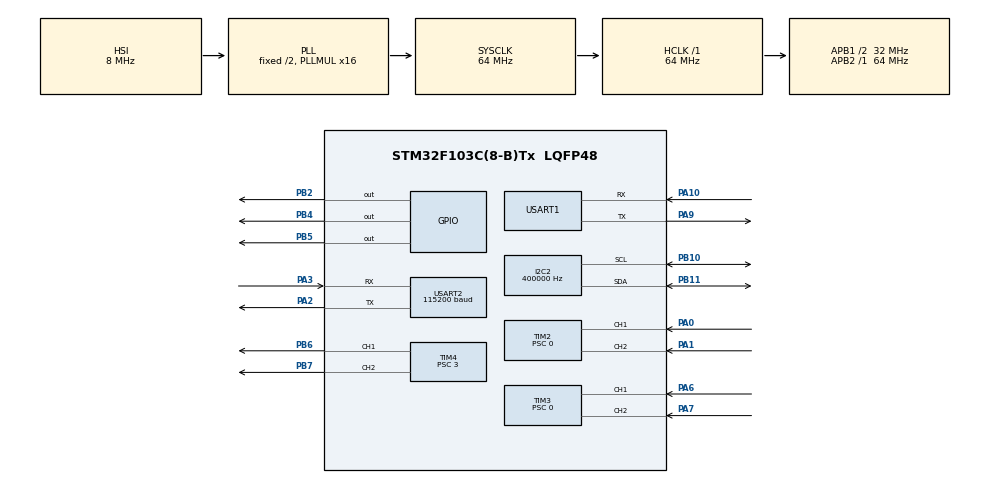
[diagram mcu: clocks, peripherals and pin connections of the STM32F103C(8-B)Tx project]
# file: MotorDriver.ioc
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Mcu.Family=STM32F1
TIM4.Channel-PWM\ Generation1\ CH1=TIM_CHANNEL_1
TIM4.AutoReloadPreload=TIM_AUTORELOAD_PRELOAD_ENABLE
PD1-OSC_OUT.Mode=HSE-External-Oscillator
PA10.Mode=Asynchronous
PB10.Mode=I2C
TIM3.AutoReloadPreload=TIM_AUTORELOAD_PRELOAD_ENABLE
PA3.GPIO_PuPd=GPIO_PULLUP
TIM3.EncoderMode=TIM_ENCODERMODE_TI12
TIM2.EncoderMode=TIM_ENCODERMODE_TI12
PD0-OSC_IN.Signal=RCC_OSC_IN
RCC.APB1CLKDivider=RCC_HCLK_DIV2
PB11.Signal=I2C2_SDA
NVIC.USART2_IRQn=true\:0\:0\:false\:false\:true\:true\:true
USART2.BaudRate=115200
RCC.SYSCLKSource=RCC_SYSCLKSOURCE_PLLCLK
ProjectManager.StackSize=0x400
PA0-WKUP.Signal=S_TIM2_CH1_ETR
PD1-OSC_OUT.Signal=RCC_OSC_OUT
PA13.Signal=SYS_JTMS-SWDIO
PA3.Mode=Asynchronous
SH.S_TIM2_CH2.0=TIM2_CH2,Encoder_Interface
PA9.Mode=Asynchronous
PB11.Mode=I2C
ProjectManager.TargetToolchain=STM32CubeIDE
RCC.HCLKFreq_Value=64000000
RCC.APB2TimFreq_Value=64000000
TIM3.Period=65535
TIM4.Pulse-PWM\ Generation1\ CH1=200
PA9.Signal=USART1_TX
PB6.Signal=S_TIM4_CH1
RCC.USBFreq_Value=64000000
TIM4.Prescaler=3
PA1.Signal=S_TIM2_CH2
RCC.AHBFreq_Value=64000000
PD0-OSC_IN.Mode=HSE-External-Oscillator
PB10.Signal=I2C2_SCL
SH.S_TIM3_CH2.0=TIM3_CH2,Encoder_Interface
PB2.Signal=GPIO_Output
board=custom
RCC.PLLMUL=RCC_PLL_MUL16
TIM4.Channel-PWM\ Generation2\ CH2=TIM_CHANNEL_2
RCC.APB2Freq_Value=64000000
PA14.Mode=Serial_Wire
TIM3.Prescaler=0
I2C2.ClockSpeed=400000
SH.S_TIM4_CH2.0=TIM4_CH2,PWM Generation2 CH2
PB7.Signal=S_TIM4_CH2
SH.S_TIM3_CH1.0=TIM3_CH1,Encoder_Interface
TIM2.Period=65535
TIM4.Period=999
PA13.Mode=Serial_Wire
Mcu.Name=STM32F103C(8-B)Tx
PB2.PinState=GPIO_PIN_RESET
PA2.Signal=USART2_TX
RCC.SYSCLKFreq_VALUE=64000000
Mcu.Package=LQFP48
PB5.Signal=GPIO_Output
TIM2.Prescaler=0
PA6.Signal=S_TIM3_CH1
USART2.VirtualMode=VM_ASYNC
USART1.VirtualMode=VM_ASYNC
SH.S_TIM2_CH1_ETR.0=TIM2_CH1,Encoder_Interface
PA10.Signal=USART1_RX
PA14.Signal=SYS_JTCK-SWCLK
ProjectManager.HeapSize=0x200
VP_TIM4_VS_ClockSourceINT.Mode=Internal
NVIC.PriorityGroup=NVIC_PRIORITYGROUP_4
SH.S_TIM4_CH1.0=TIM4_CH1,PWM Generation1 CH1
RCC.APB1TimFreq_Value=64000000
PA2.Mode=Asynchronous
TIM2.AutoReloadPreload=TIM_AUTORELOAD_PRELOAD_DISABLE
PB6.GPIO_Speed=GPIO_SPEED_FREQ_MEDIUM
NVIC.USART1_IRQn=true\:0\:0\:false\:false\:true\:true\:true
RCC.APB1Freq_Value=32000000
I2C2.I2C_Mode=I2C_Fast
TIM4.Pulse-PWM\ Generation2\ CH2=800
PB4.Signal=GPIO_Output
PA3.Signal=USART2_RX
PA7.Signal=S_TIM3_CH2
PB7.GPIO_Speed=GPIO_SPEED_FREQ_MEDIUM

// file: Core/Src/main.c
/* USER CODE BEGIN Header */
/**
  ******************************************************************************
  * @file           : main.c
  * @brief          : Main program body
  ******************************************************************************
  * @attention
  *
  * <h2><center>&copy; Copyright (c) 2021 STMicroelectronics.
  * All rights reserved.</center></h2>
  *
  * This software component is licensed by ST under BSD 3-Clause license,
  * the "License"; You may not use this file except in compliance with the
  * License. You may obtain a copy of the License at:
  *                        opensource.org/licenses/BSD-3-Clause
  *
  ******************************************************************************
  */
/* USER CODE END Header */
#include "main.h"
#include "i2c.h"
#include "tim.h"
#include "usart.h"
#include "gpio.h"

/* USER CODE BEGIN Includes */
#include <string.h>
/* USER CODE END Includes */

void SystemClock_Config(void);

int main(void)
{

  /* MCU Configuration--------------------------------------------------------*/

  /* Reset of all peripherals, Initializes the Flash interface and the Systick. */
  HAL_Init();

  /* Configure the system clock */
  SystemClock_Config();

  /* Initialize all configured peripherals */
  MX_GPIO_Init();
  MX_TIM4_Init();
  MX_USART1_UART_Init();
  MX_TIM2_Init();
  MX_TIM3_Init();
  MX_USART2_UART_Init();
  MX_I2C2_Init();
  /* USER CODE BEGIN 2 */

  setup();

  /* USER CODE END 2 */

  /* Infinite loop */
  /* USER CODE BEGIN WHILE */

  while(1){
	  TestMotorMenu();
  }
  while (1)
  {
	  loop();

    /* USER CODE END WHILE */

  }
}

void SystemClock_Config(void)
{
  RCC_OscInitTypeDef RCC_OscInitStruct = {0};
  RCC_ClkInitTypeDef RCC_ClkInitStruct = {0};

  /** Initializes the RCC Oscillators according to the specified parameters
  * in the RCC_OscInitTypeDef structure.
  */
  RCC_OscInitStruct.OscillatorType = RCC_OSCILLATORTYPE_HSI;
  RCC_OscInitStruct.HSIState = RCC_HSI_ON;
  RCC_OscInitStruct.HSICalibrationValue = RCC_HSICALIBRATION_DEFAULT;
  RCC_OscInitStruct.PLL.PLLState = RCC_PLL_ON;
  RCC_OscInitStruct.PLL.PLLSource = RCC_PLLSOURCE_HSI_DIV2;
  RCC_OscInitStruct.PLL.PLLMUL = RCC_PLL_MUL16;
  if (HAL_RCC_OscConfig(&RCC_OscInitStruct) != HAL_OK)
  {
    Error_Handler();
  }
  /** Initializes the CPU, AHB and APB buses clocks
  */
  RCC_ClkInitStruct.ClockType = RCC_CLOCKTYPE_HCLK|RCC_CLOCKTYPE_SYSCLK
                              |RCC_CLOCKTYPE_PCLK1|RCC_CLOCKTYPE_PCLK2;
  RCC_ClkInitStruct.SYSCLKSource = RCC_SYSCLKSOURCE_PLLCLK;
  RCC_ClkInitStruct.AHBCLKDivider = RCC_SYSCLK_DIV1;
  RCC_ClkInitStruct.APB1CLKDivider = RCC_HCLK_DIV2;
  RCC_ClkInitStruct.APB2CLKDivider = RCC_HCLK_DIV1;

  if (HAL_RCC_ClockConfig(&RCC_ClkInitStruct, FLASH_LATENCY_2) != HAL_OK)
  {
    Error_Handler();
  }
}

void Error_Handler(void)
{
  __disable_irq();
  while (1)
  {
  }
}

/************************ (C) COPYRIGHT STMicroelectronics *****END OF FILE****/
